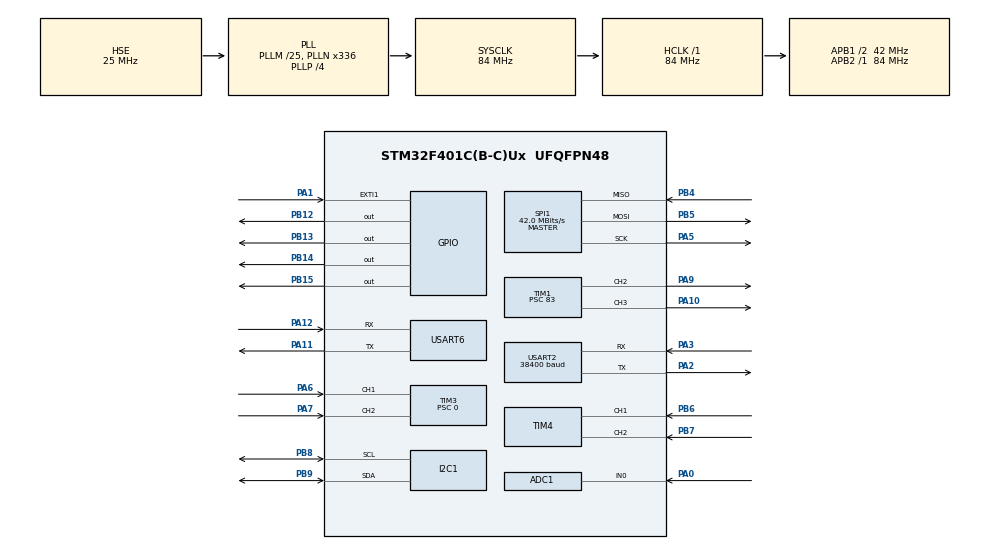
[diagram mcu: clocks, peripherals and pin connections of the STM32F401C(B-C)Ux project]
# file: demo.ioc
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ADC1.Channel-3\#ChannelRegularConversion=ADC_CHANNEL_0
ADC1.NbrOfConversionFlag=1
ADC1.Rank-3\#ChannelRegularConversion=1
ADC1.SamplingTime-3\#ChannelRegularConversion=ADC_SAMPLETIME_3CYCLES
ADC1.master=1
I2C1.I2C_Mode=I2C_Fast
Mcu.Family=STM32F4
Mcu.Name=STM32F401C(B-C)Ux
Mcu.Package=UFQFPN48
NVIC.EXTI1_IRQn=true\:3\:0\:true\:false\:true\:true\:true\:true
NVIC.PriorityGroup=NVIC_PRIORITYGROUP_4
NVIC.TIM2_IRQn=true\:1\:0\:true\:false\:true\:true\:true\:true
NVIC.TIM3_IRQn=true\:0\:0\:false\:false\:true\:true\:true\:true
NVIC.TIM4_IRQn=true\:0\:0\:false\:false\:true\:true\:true\:true
NVIC.USART2_IRQn=true\:0\:0\:false\:false\:true\:true\:true\:true
PA0-WKUP.Signal=ADCx_IN0
PA1.GPIO_ModeDefaultEXTI=GPIO_MODE_IT_FALLING
PA1.GPIO_PuPd=GPIO_PULLUP
PA1.Signal=GPXTI1
PA10.Signal=S_TIM1_CH3
PA11.Mode=Asynchronous
PA11.Signal=USART6_TX
PA12.Mode=Asynchronous
PA12.Signal=USART6_RX
PA13.Mode=Serial_Wire
PA13.Signal=SYS_JTMS-SWDIO
PA14.Mode=Serial_Wire
PA14.Signal=SYS_JTCK-SWCLK
PA2.Mode=Asynchronous
PA2.Signal=USART2_TX
PA3.Mode=Asynchronous
PA3.Signal=USART2_RX
PA5.Mode=Full_Duplex_Master
PA5.Signal=SPI1_SCK
PA6.Signal=S_TIM3_CH1
PA7.Signal=S_TIM3_CH2
PA9.Signal=S_TIM1_CH2
PB12.GPIO_Speed=GPIO_SPEED_FREQ_HIGH
PB12.PinState=GPIO_PIN_SET
PB12.Signal=GPIO_Output
PB13.GPIO_Speed=GPIO_SPEED_FREQ_HIGH
PB13.Signal=GPIO_Output
PB14.GPIO_Speed=GPIO_SPEED_FREQ_HIGH
PB14.PinState=GPIO_PIN_SET
PB14.Signal=GPIO_Output
PB15.GPIO_Speed=GPIO_SPEED_FREQ_HIGH
PB15.Signal=GPIO_Output
PB4.Mode=Full_Duplex_Master
PB4.Signal=SPI1_MISO
PB5.Mode=Full_Duplex_Master
PB5.Signal=SPI1_MOSI
PB6.Signal=S_TIM4_CH1
PB7.Signal=S_TIM4_CH2
PB8.Mode=I2C
PB8.Signal=I2C1_SCL
PB9.Mode=I2C
PB9.Signal=I2C1_SDA
PH0\ -\ OSC_IN.Mode=HSE-External-Oscillator
PH0\ -\ OSC_IN.Signal=RCC_OSC_IN
PH1\ -\ OSC_OUT.Mode=HSE-External-Oscillator
PH1\ -\ OSC_OUT.Signal=RCC_OSC_OUT
ProjectManager.HeapSize=0x200
ProjectManager.StackSize=0x400
ProjectManager.TargetToolchain=STM32CubeIDE
RCC.48MHZClocksFreq_Value=84000000
RCC.AHBFreq_Value=84000000
RCC.APB1CLKDivider=RCC_HCLK_DIV2
RCC.APB1Freq_Value=42000000
RCC.APB1TimFreq_Value=84000000
RCC.APB2Freq_Value=84000000
RCC.APB2TimFreq_Value=84000000
RCC.CortexFreq_Value=84000000
RCC.HCLKFreq_Value=84000000
RCC.HSE_VALUE=25000000
RCC.HSI_VALUE=16000000
RCC.LSE_VALUE=32768
RCC.PLLM=25
RCC.PLLN=336
RCC.PLLP=RCC_PLLP_DIV4
RCC.PLLSourceVirtual=RCC_PLLSOURCE_HSE
RCC.SYSCLKFreq_VALUE=84000000
RCC.SYSCLKSource=RCC_SYSCLKSOURCE_PLLCLK
RCC.VCOOutputFreq_Value=336000000
SH.ADCx_IN0.0=ADC1_IN0,IN0
SH.S_TIM1_CH2.0=TIM1_CH2,PWM Generation2 CH2
SH.S_TIM1_CH3.0=TIM1_CH3,PWM Generation3 CH3
SH.S_TIM3_CH1.0=TIM3_CH1,Encoder_Interface
SH.S_TIM3_CH2.0=TIM3_CH2,Encoder_Interface
SH.S_TIM4_CH1.0=TIM4_CH1,Encoder_Interface
SH.S_TIM4_CH2.0=TIM4_CH2,Encoder_Interface
SPI1.CalculateBaudRate=42.0 MBits/s
SPI1.Direction=SPI_DIRECTION_2LINES
SPI1.Mode=SPI_MODE_MASTER
SPI1.VirtualType=VM_MASTER
TIM1.Channel-PWM\ Generation2\ CH2=TIM_CHANNEL_2
TIM1.Channel-PWM\ Generation3\ CH3=TIM_CHANNEL_3
TIM1.Period=9999
TIM1.Prescaler=83
TIM2.AutoReloadPreload=TIM_AUTORELOAD_PRELOAD_ENABLE
TIM2.Period=9999
TIM2.Prescaler=83
TIM3.EncoderMode=TIM_ENCODERMODE_TI12
TIM3.Prescaler=0
TIM4.EncoderMode=TIM_ENCODERMODE_TI12
USART2.BaudRate=38400
USART2.VirtualMode=VM_ASYNC
USART6.VirtualMode=VM_ASYNC
VP_TIM1_VS_ClockSourceINT.Mode=Internal
VP_TIM2_VS_ClockSourceINT.Mode=Internal
board=custom

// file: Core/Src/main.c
/* USER CODE BEGIN Header */
/**
  ******************************************************************************
  * @file           : main.c
  * @brief          : Main program body
  ******************************************************************************
  * @attention
  *
  * Copyright (c) 2022 STMicroelectronics.
  * All rights reserved.
  *
  * This software is licensed under terms that can be found in the LICENSE file
  * in the root directory of this software component.
  * If no LICENSE file comes with this software, it is provided AS-IS.
  *
  ******************************************************************************
  */
/* USER CODE END Header */
#include "main.h"

/* USER CODE BEGIN Includes */
#include "UserMain.h"
/* USER CODE END Includes */

ADC_HandleTypeDef hadc1;

I2C_HandleTypeDef hi2c1;

SPI_HandleTypeDef hspi1;

TIM_HandleTypeDef htim1;
TIM_HandleTypeDef htim2;
TIM_HandleTypeDef htim3;
TIM_HandleTypeDef htim4;

UART_HandleTypeDef huart2;
UART_HandleTypeDef huart6;

void SystemClock_Config(void);
static void MX_GPIO_Init(void);
static void MX_TIM2_Init(void);
static void MX_TIM1_Init(void);
static void MX_TIM3_Init(void);
static void MX_TIM4_Init(void);
static void MX_USART2_UART_Init(void);
static void MX_I2C1_Init(void);
static void MX_SPI1_Init(void);
static void MX_USART6_UART_Init(void);
static void MX_ADC1_Init(void);

int main(void)
{

  /* MCU Configuration--------------------------------------------------------*/

  /* Reset of all peripherals, Initializes the Flash interface and the Systick. */
  HAL_Init();

  /* Configure the system clock */
  SystemClock_Config();

  /* Initialize all configured peripherals */
  MX_GPIO_Init();
  MX_TIM2_Init();
  MX_TIM1_Init();
  MX_TIM3_Init();
  MX_TIM4_Init();
  MX_USART2_UART_Init();
  MX_I2C1_Init();
  MX_SPI1_Init();
  MX_USART6_UART_Init();
  MX_ADC1_Init();
  /* USER CODE BEGIN 2 */
    UserConfigInit();
    UserSysInit();
  /* USER CODE END 2 */

  /* Infinite loop */
    while (1) {

    /* USER CODE BEGIN 3 */
    UserLoop();
    }
  /* USER CODE END 3 */
}

void SystemClock_Config(void)
{
  RCC_OscInitTypeDef RCC_OscInitStruct = {0};
  RCC_ClkInitTypeDef RCC_ClkInitStruct = {0};

  /** Configure the main internal regulator output voltage
  */
  __HAL_RCC_PWR_CLK_ENABLE();
  __HAL_PWR_VOLTAGESCALING_CONFIG(PWR_REGULATOR_VOLTAGE_SCALE2);

  /** Initializes the RCC Oscillators according to the specified parameters
  * in the RCC_OscInitTypeDef structure.
  */
  RCC_OscInitStruct.OscillatorType = RCC_OSCILLATORTYPE_HSE;
  RCC_OscInitStruct.HSEState = RCC_HSE_ON;
  RCC_OscInitStruct.PLL.PLLState = RCC_PLL_ON;
  RCC_OscInitStruct.PLL.PLLSource = RCC_PLLSOURCE_HSE;
  RCC_OscInitStruct.PLL.PLLM = 25;
  RCC_OscInitStruct.PLL.PLLN = 336;
  RCC_OscInitStruct.PLL.PLLP = RCC_PLLP_DIV4;
  RCC_OscInitStruct.PLL.PLLQ = 4;
  if (HAL_RCC_OscConfig(&RCC_OscInitStruct) != HAL_OK)
  {
    Error_Handler();
  }

  /** Initializes the CPU, AHB and APB buses clocks
  */
  RCC_ClkInitStruct.ClockType = RCC_CLOCKTYPE_HCLK|RCC_CLOCKTYPE_SYSCLK
                              |RCC_CLOCKTYPE_PCLK1|RCC_CLOCKTYPE_PCLK2;
  RCC_ClkInitStruct.SYSCLKSource = RCC_SYSCLKSOURCE_PLLCLK;
  RCC_ClkInitStruct.AHBCLKDivider = RCC_SYSCLK_DIV1;
  RCC_ClkInitStruct.APB1CLKDivider = RCC_HCLK_DIV2;
  RCC_ClkInitStruct.APB2CLKDivider = RCC_HCLK_DIV1;

  if (HAL_RCC_ClockConfig(&RCC_ClkInitStruct, FLASH_LATENCY_2) != HAL_OK)
  {
    Error_Handler();
  }
}

static void MX_ADC1_Init(void)
{

  ADC_ChannelConfTypeDef sConfig = {0};

  /** Configure the global features of the ADC (Clock, Resolution, Data Alignment and number of conversion)
  */
  hadc1.Instance = ADC1;
  hadc1.Init.ClockPrescaler = ADC_CLOCK_SYNC_PCLK_DIV4;
  hadc1.Init.Resolution = ADC_RESOLUTION_12B;
  hadc1.Init.ScanConvMode = DISABLE;
  hadc1.Init.ContinuousConvMode = DISABLE;
  hadc1.Init.DiscontinuousConvMode = DISABLE;
  hadc1.Init.ExternalTrigConvEdge = ADC_EXTERNALTRIGCONVEDGE_NONE;
  hadc1.Init.ExternalTrigConv = ADC_SOFTWARE_START;
  hadc1.Init.DataAlign = ADC_DATAALIGN_RIGHT;
  hadc1.Init.NbrOfConversion = 1;
  hadc1.Init.DMAContinuousRequests = DISABLE;
  hadc1.Init.EOCSelection = ADC_EOC_SINGLE_CONV;
  if (HAL_ADC_Init(&hadc1) != HAL_OK)
  {
    Error_Handler();
  }

  /** Configure for the selected ADC regular channel its corresponding rank in the sequencer and its sample time.
  */
  sConfig.Channel = ADC_CHANNEL_0;
  sConfig.Rank = 1;
  sConfig.SamplingTime = ADC_SAMPLETIME_3CYCLES;
  if (HAL_ADC_ConfigChannel(&hadc1, &sConfig) != HAL_OK)
  {
    Error_Handler();
  }

}

static void MX_I2C1_Init(void)
{

  hi2c1.Instance = I2C1;
  hi2c1.Init.ClockSpeed = 400000;
  hi2c1.Init.DutyCycle = I2C_DUTYCYCLE_2;
  hi2c1.Init.OwnAddress1 = 0;
  hi2c1.Init.AddressingMode = I2C_ADDRESSINGMODE_7BIT;
  hi2c1.Init.DualAddressMode = I2C_DUALADDRESS_DISABLE;
  hi2c1.Init.OwnAddress2 = 0;
  hi2c1.Init.GeneralCallMode = I2C_GENERALCALL_DISABLE;
  hi2c1.Init.NoStretchMode = I2C_NOSTRETCH_DISABLE;
  if (HAL_I2C_Init(&hi2c1) != HAL_OK)
  {
    Error_Handler();
  }

}

static void MX_SPI1_Init(void)
{

  /* SPI1 parameter configuration*/
  hspi1.Instance = SPI1;
  hspi1.Init.Mode = SPI_MODE_MASTER;
  hspi1.Init.Direction = SPI_DIRECTION_2LINES;
  hspi1.Init.DataSize = SPI_DATASIZE_8BIT;
  hspi1.Init.CLKPolarity = SPI_POLARITY_LOW;
  hspi1.Init.CLKPhase = SPI_PHASE_1EDGE;
  hspi1.Init.NSS = SPI_NSS_SOFT;
  hspi1.Init.BaudRatePrescaler = SPI_BAUDRATEPRESCALER_2;
  hspi1.Init.FirstBit = SPI_FIRSTBIT_MSB;
  hspi1.Init.TIMode = SPI_TIMODE_DISABLE;
  hspi1.Init.CRCCalculation = SPI_CRCCALCULATION_DISABLE;
  hspi1.Init.CRCPolynomial = 10;
  if (HAL_SPI_Init(&hspi1) != HAL_OK)
  {
    Error_Handler();
  }

}

static void MX_TIM1_Init(void)
{

  TIM_ClockConfigTypeDef sClockSourceConfig = {0};
  TIM_MasterConfigTypeDef sMasterConfig = {0};
  TIM_OC_InitTypeDef sConfigOC = {0};
  TIM_BreakDeadTimeConfigTypeDef sBreakDeadTimeConfig = {0};

  htim1.Instance = TIM1;
  htim1.Init.Prescaler = 83;
  htim1.Init.CounterMode = TIM_COUNTERMODE_UP;
  htim1.Init.Period = 9999;
  htim1.Init.ClockDivision = TIM_CLOCKDIVISION_DIV1;
  htim1.Init.RepetitionCounter = 0;
  htim1.Init.AutoReloadPreload = TIM_AUTORELOAD_PRELOAD_DISABLE;
  if (HAL_TIM_Base_Init(&htim1) != HAL_OK)
  {
    Error_Handler();
  }
  sClockSourceConfig.ClockSource = TIM_CLOCKSOURCE_INTERNAL;
  if (HAL_TIM_ConfigClockSource(&htim1, &sClockSourceConfig) != HAL_OK)
  {
    Error_Handler();
  }
  if (HAL_TIM_PWM_Init(&htim1) != HAL_OK)
  {
    Error_Handler();
  }
  sMasterConfig.MasterOutputTrigger = TIM_TRGO_RESET;
  sMasterConfig.MasterSlaveMode = TIM_MASTERSLAVEMODE_DISABLE;
  if (HAL_TIMEx_MasterConfigSynchronization(&htim1, &sMasterConfig) != HAL_OK)
  {
    Error_Handler();
  }
  sConfigOC.OCMode = TIM_OCMODE_PWM1;
  sConfigOC.Pulse = 0;
  sConfigOC.OCPolarity = TIM_OCPOLARITY_HIGH;
  sConfigOC.OCNPolarity = TIM_OCNPOLARITY_HIGH;
  sConfigOC.OCFastMode = TIM_OCFAST_DISABLE;
  sConfigOC.OCIdleState = TIM_OCIDLESTATE_RESET;
  sConfigOC.OCNIdleState = TIM_OCNIDLESTATE_RESET;
  if (HAL_TIM_PWM_ConfigChannel(&htim1, &sConfigOC, TIM_CHANNEL_2) != HAL_OK)
  {
    Error_Handler();
  }
  if (HAL_TIM_PWM_ConfigChannel(&htim1, &sConfigOC, TIM_CHANNEL_3) != HAL_OK)
  {
    Error_Handler();
  }
  sBreakDeadTimeConfig.OffStateRunMode = TIM_OSSR_DISABLE;
  sBreakDeadTimeConfig.OffStateIDLEMode = TIM_OSSI_DISABLE;
  sBreakDeadTimeConfig.LockLevel = TIM_LOCKLEVEL_OFF;
  sBreakDeadTimeConfig.DeadTime = 0;
  sBreakDeadTimeConfig.BreakState = TIM_BREAK_DISABLE;
  sBreakDeadTimeConfig.BreakPolarity = TIM_BREAKPOLARITY_HIGH;
  sBreakDeadTimeConfig.AutomaticOutput = TIM_AUTOMATICOUTPUT_DISABLE;
  if (HAL_TIMEx_ConfigBreakDeadTime(&htim1, &sBreakDeadTimeConfig) != HAL_OK)
  {
    Error_Handler();
  }
  HAL_TIM_MspPostInit(&htim1);

}

static void MX_TIM2_Init(void)
{

  TIM_ClockConfigTypeDef sClockSourceConfig = {0};
  TIM_MasterConfigTypeDef sMasterConfig = {0};

  htim2.Instance = TIM2;
  htim2.Init.Prescaler = 83;
  htim2.Init.CounterMode = TIM_COUNTERMODE_UP;
  htim2.Init.Period = 9999;
  htim2.Init.ClockDivision = TIM_CLOCKDIVISION_DIV1;
  htim2.Init.AutoReloadPreload = TIM_AUTORELOAD_PRELOAD_ENABLE;
  if (HAL_TIM_Base_Init(&htim2) != HAL_OK)
  {
    Error_Handler();
  }
  sClockSourceConfig.ClockSource = TIM_CLOCKSOURCE_INTERNAL;
  if (HAL_TIM_ConfigClockSource(&htim2, &sClockSourceConfig) != HAL_OK)
  {
    Error_Handler();
  }
  sMasterConfig.MasterOutputTrigger = TIM_TRGO_RESET;
  sMasterConfig.MasterSlaveMode = TIM_MASTERSLAVEMODE_DISABLE;
  if (HAL_TIMEx_MasterConfigSynchronization(&htim2, &sMasterConfig) != HAL_OK)
  {
    Error_Handler();
  }

}

static void MX_TIM3_Init(void)
{

  TIM_Encoder_InitTypeDef sConfig = {0};
  TIM_MasterConfigTypeDef sMasterConfig = {0};

  htim3.Instance = TIM3;
  htim3.Init.Prescaler = 0;
  htim3.Init.CounterMode = TIM_COUNTERMODE_UP;
  htim3.Init.Period = 65535;
  htim3.Init.ClockDivision = TIM_CLOCKDIVISION_DIV1;
  htim3.Init.AutoReloadPreload = TIM_AUTORELOAD_PRELOAD_DISABLE;
  sConfig.EncoderMode = TIM_ENCODERMODE_TI12;
  sConfig.IC1Polarity = TIM_ICPOLARITY_RISING;
  sConfig.IC1Selection = TIM_ICSELECTION_DIRECTTI;
  sConfig.IC1Prescaler = TIM_ICPSC_DIV1;
  sConfig.IC1Filter = 0;
  sConfig.IC2Polarity = TIM_ICPOLARITY_RISING;
  sConfig.IC2Selection = TIM_ICSELECTION_DIRECTTI;
  sConfig.IC2Prescaler = TIM_ICPSC_DIV1;
  sConfig.IC2Filter = 0;
  if (HAL_TIM_Encoder_Init(&htim3, &sConfig) != HAL_OK)
  {
    Error_Handler();
  }
  sMasterConfig.MasterOutputTrigger = TIM_TRGO_RESET;
  sMasterConfig.MasterSlaveMode = TIM_MASTERSLAVEMODE_DISABLE;
  if (HAL_TIMEx_MasterConfigSynchronization(&htim3, &sMasterConfig) != HAL_OK)
  {
    Error_Handler();
  }

}

static void MX_TIM4_Init(void)
{

  TIM_Encoder_InitTypeDef sConfig = {0};
  TIM_MasterConfigTypeDef sMasterConfig = {0};

  htim4.Instance = TIM4;
  htim4.Init.Prescaler = 0;
  htim4.Init.CounterMode = TIM_COUNTERMODE_UP;
  htim4.Init.Period = 65535;
  htim4.Init.ClockDivision = TIM_CLOCKDIVISION_DIV1;
  htim4.Init.AutoReloadPreload = TIM_AUTORELOAD_PRELOAD_DISABLE;
  sConfig.EncoderMode = TIM_ENCODERMODE_TI12;
  sConfig.IC1Polarity = TIM_ICPOLARITY_RISING;
  sConfig.IC1Selection = TIM_ICSELECTION_DIRECTTI;
  sConfig.IC1Prescaler = TIM_ICPSC_DIV1;
  sConfig.IC1Filter = 0;
  sConfig.IC2Polarity = TIM_ICPOLARITY_RISING;
  sConfig.IC2Selection = TIM_ICSELECTION_DIRECTTI;
  sConfig.IC2Prescaler = TIM_ICPSC_DIV1;
  sConfig.IC2Filter = 0;
  if (HAL_TIM_Encoder_Init(&htim4, &sConfig) != HAL_OK)
  {
    Error_Handler();
  }
  sMasterConfig.MasterOutputTrigger = TIM_TRGO_RESET;
  sMasterConfig.MasterSlaveMode = TIM_MASTERSLAVEMODE_DISABLE;
  if (HAL_TIMEx_MasterConfigSynchronization(&htim4, &sMasterConfig) != HAL_OK)
  {
    Error_Handler();
  }

}

static void MX_USART2_UART_Init(void)
{

  huart2.Instance = USART2;
  huart2.Init.BaudRate = 38400;
  huart2.Init.WordLength = UART_WORDLENGTH_8B;
  huart2.Init.StopBits = UART_STOPBITS_1;
  huart2.Init.Parity = UART_PARITY_NONE;
  huart2.Init.Mode = UART_MODE_TX_RX;
  huart2.Init.HwFlowCtl = UART_HWCONTROL_NONE;
  huart2.Init.OverSampling = UART_OVERSAMPLING_16;
  if (HAL_UART_Init(&huart2) != HAL_OK)
  {
    Error_Handler();
  }

}

static void MX_USART6_UART_Init(void)
{

  huart6.Instance = USART6;
  huart6.Init.BaudRate = 115200;
  huart6.Init.WordLength = UART_WORDLENGTH_8B;
  huart6.Init.StopBits = UART_STOPBITS_1;
  huart6.Init.Parity = UART_PARITY_NONE;
  huart6.Init.Mode = UART_MODE_TX_RX;
  huart6.Init.HwFlowCtl = UART_HWCONTROL_NONE;
  huart6.Init.OverSampling = UART_OVERSAMPLING_16;
  if (HAL_UART_Init(&huart6) != HAL_OK)
  {
    Error_Handler();
  }

}

static void MX_GPIO_Init(void)
{
  GPIO_InitTypeDef GPIO_InitStruct = {0};

  /* GPIO Ports Clock Enable */
  __HAL_RCC_GPIOH_CLK_ENABLE();
  __HAL_RCC_GPIOA_CLK_ENABLE();
  __HAL_RCC_GPIOB_CLK_ENABLE();

  /*Configure GPIO pin Output Level */
  HAL_GPIO_WritePin(GPIOB, GPIO_PIN_12|GPIO_PIN_14, GPIO_PIN_SET);

  /*Configure GPIO pin Output Level */
  HAL_GPIO_WritePin(GPIOB, GPIO_PIN_13|GPIO_PIN_15, GPIO_PIN_RESET);

  /*Configure GPIO pin : PA1 */
  GPIO_InitStruct.Pin = GPIO_PIN_1;
  GPIO_InitStruct.Mode = GPIO_MODE_IT_FALLING;
  GPIO_InitStruct.Pull = GPIO_PULLUP;
  HAL_GPIO_Init(GPIOA, &GPIO_InitStruct);

  /*Configure GPIO pins : PB12 PB13 PB14 PB15 */
  GPIO_InitStruct.Pin = GPIO_PIN_12|GPIO_PIN_13|GPIO_PIN_14|GPIO_PIN_15;
  GPIO_InitStruct.Mode = GPIO_MODE_OUTPUT_PP;
  GPIO_InitStruct.Pull = GPIO_NOPULL;
  GPIO_InitStruct.Speed = GPIO_SPEED_FREQ_HIGH;
  HAL_GPIO_Init(GPIOB, &GPIO_InitStruct);

  /* EXTI interrupt init*/
  HAL_NVIC_SetPriority(EXTI1_IRQn, 3, 0);
  HAL_NVIC_EnableIRQ(EXTI1_IRQn);

}

void Error_Handler(void)
{
    __disable_irq();
    while (1) {
    }
}
